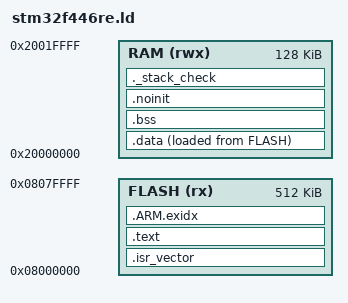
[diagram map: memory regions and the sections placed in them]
/* STM32F446RE: 512 KB of flash, 128 KB of SRAM */

ENTRY(Reset_Handler)

MEMORY
{
    FLASH (rx)  : ORIGIN = 0x08000000, LENGTH = 512K
    RAM   (rwx) : ORIGIN = 0x20000000, LENGTH = 128K
}

_estack = ORIGIN(RAM) + LENGTH(RAM);
_min_stack = 0x800;     /* main's stack until the scheduler starts, then the interrupts' */

SECTIONS
{
    .isr_vector :
    {
        . = ALIGN(4);
        KEEP(*(.isr_vector))
        . = ALIGN(4);
    } > FLASH

    .text :
    {
        . = ALIGN(4);
        *(.text*)
        *(.rodata*)
        KEEP(*(.init))
        KEEP(*(.fini))
        . = ALIGN(4);
        _etext = .;
    } > FLASH

    .ARM.exidx :
    {
        *(.ARM.exidx*)
    } > FLASH

    _sidata = LOADADDR(.data);

    .data :
    {
        . = ALIGN(4);
        _sdata = .;
        *(.data*)
        . = ALIGN(4);
        _edata = .;
    } > RAM AT > FLASH

    .bss (NOLOAD) :
    {
        . = ALIGN(4);
        _sbss = .;
        *(.bss*)
        *(COMMON)
        . = ALIGN(4);
        _ebss = .;
    } > RAM

    /* Kept across a reset: the fault record */
    .noinit (NOLOAD) :
    {
        . = ALIGN(4);
        *(.noinit*)
        . = ALIGN(4);
    } > RAM

    ._stack_check (NOLOAD) :
    {
        . = ALIGN(8);
        . = . + _min_stack;
    } > RAM
}
